AUTOSAR XML (schema 4-2-1)
package /RootP_ASWC_M740
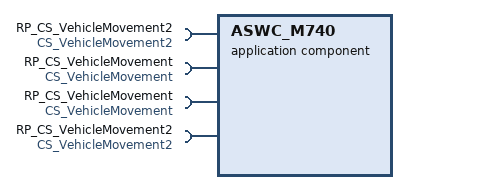
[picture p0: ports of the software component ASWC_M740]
  application sw component type ASWC_M740
    4 x require port:
      RP_CS_VehicleMovement2: required-interface=CS_VehicleMovement2
      RP_CS_VehicleMovement: required-interface=CS_VehicleMovement
      RP_CS_VehicleMovement: required-interface=CS_VehicleMovement
      RP_CS_VehicleMovement2: required-interface=CS_VehicleMovement2
package /RootP_Composition
  composition sw component type Compo_VSM
    component Instance_ASWC_M740: type=ASWC_M740
